# STM32WL31 register map
File version: 1.1
CPU: CM0+ r0p0, little endian, MPU, no FPU, 4 interrupt priority bits
Registers are 32-bit, read-write, reset 0x0 unless marked. A register's access mark holds for its fields unless they carry their own. Offsets are from the block's base; [hi:lo] are bit positions.

## RCC
Base 0x48400000
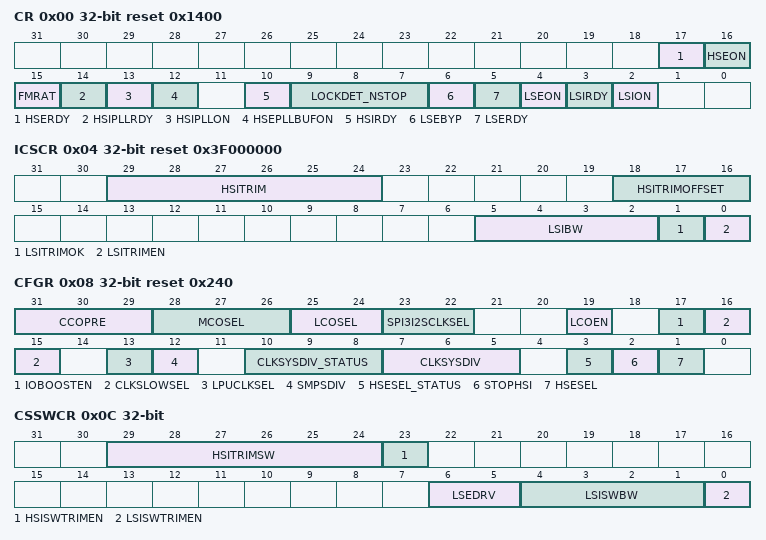
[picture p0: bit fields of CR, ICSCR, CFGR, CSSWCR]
0x00 CR reset 0x1400
  [17] HSERDY ro — External High Speed Clock ready flag. Set by hardware to indicate that HSE oscillator is stable. 0: HSE oscillator not ready 1: HSE oscillator ready
  [16] HSEON — External High Speed Clock enable. Set and reset by software. in low power mode, HSE is turned off. HSE is turned ON only when RFSUBG LDO is Ready 0: HSE oscillator OFF 1: HSE oscillator ON
  [15] FMRAT — Force MRSUBG accurate clock ready status (for debug purpose) 0: no effect 1: active_transmission is force to '1' whatever the HSIPLLRDY/HSE status
  [14] HSIPLLRDY ro — Internal High Speed Clock PLL ready flag. 0: PLL is unlocked 1: PLL is locked
  [13] HSIPLLON — Internal High Speed Clock PLL enable 0: PLL is OFF 1: PLL is ON
  [12] HSEPLLBUFON — External High Speed Clock Buffer for PLL RF enable. Set and reset by software. 0: HSE PLL Buffer OFF 1: HSE PLL Buffer ON (default)
  [10] HSIRDY ro — Internal High Speed clock ready flag. Set by hardware to indicate that internal RC 64MHz oscillator is stable. This bit is activated only if the RC is enabled by HSION (it is not activated if the RC is enabled by an IP request). 0: internal RC 64 MHz oscillator not ready 1: internal RC 64 MHz oscillator ready
  [9:7] LOCKDET_NSTOP — Lock detector Nstop value When start_stop signal is high; a counter is incremented every 16 MHz clock cycle. When the counter reaches (NSTOP+1) x 64 value, the lock_det signal is set high indicating that the PLL is locked. As soon as the start_stop signal is low the counter is reset to 0.
  [6] LSEBYP — External Low Speed Clock bypass. Set and reset by software. Reset source only for this field: PORESETn 0: LSE oscillator bypass OFF 1: LSE oscillator bypass ON Note that enablng this bit, the configuration of PB13 will be bypassed (whatever DFTMUX or AF selection)
  [5] LSERDY ro — External Low Speed Clock ready flag. Set by hardware to indicate that LSE oscillator is stable. 0: LSE oscillator not ready 1: LSE oscillator ready
  [4] LSEON — External Low Speed Clock enable. Set and reset by software. Reset source only for this field: PORESETn 0: LSE oscillator OFF 1: LSE oscillator ON Note that enablng this bit, the configuration of PB12 and PB13 will be bypassed (whatever DFTMUX or AF selection)
  [3] LSIRDY ro — Internal Low Speed oscillator Ready Set and reset by hardware to indicate when the Low Speed Internal RC oscillator is stable. Reset source only for this field: PORESETn 0: LSI RC oscillator not ready 1: LSI RC oscillator ready
  [2] LSION — Internal Low Speed oscillator enable Set and reset by software. Reset source only for this field: PORESETn 0: LSI RC oscillator OFF 1: LSI RC oscillator ON
0x04 ICSCR reset 0x3F000000
  [29:24] HSITRIM ro — High Speed Internal clock trimming. This value is loaded soon after the completion of the Option Byte Loading procedure. When max value 0x3f is set, HSI is less than 64MHz
  [18:16] HSITRIMOFFSET — ICSCR[18:16] = HSITRIMOFFSET[2:0]: High Speed oscillator signed trimming offset 000: 0 (+ 0 MHz / default) 001: 1 (-0.5 MHz) 010: 2 (-1MHz) 011: 3 (-1.5 MHz) 100: -1 (+2 MHz) 101: -2 (+1.5MHz) 110: -3 (+1 MHz) 111: -4 (+0.5 MHz)
  [5:2] LSIBW ro — Trimming in test mode The value stored is the correspondent Engi Byte and represents the actual value driving the input of the hardware macro. This value is loaded soon after the completion of the Option Byte Loading procedure. This field is directly writeable only in Test Mode.
  [1] LSITRIMOK ro — LSITRIMOK: Low Speed oscillator trimming OK Set and reset by hardware to indicate when the Low Speed Internal RC oscillator has reached an optimal trimming of its bias current; this bit is only valid when LSITRIMEN is active. 0: LSI Bias trimming (LSIBW) is not good 1: LSI Bias trimming (LSIBW) value is OK
  [0] LSITRIMEN — Low Speed oscillator trimming enable Set and reset by software. Reset source only for this field: PORESETn 0: LSI oscillator Bias trimming disabled 1: LSI oscillator Bias trimming enabled
0x08 CFGR reset 0x240
  [31:29] CCOPRE — Configurable Clock Output Prescaler. Set and reset by software. Glitches propagation if CCOPRE is modified after CCO output is enabled. 000: CCO clock is divided by 1 001: CCO clock is divided by 2 010: CCO clock is divided by 4 011: CCO clock is divided by 8 100: CCO clock is divided by 16 101: CCO clock is divided by 32 Others: not used
  [28:26] MCOSEL — Main Configurable Clock Output Selection. Set and reset by software. Glitches propagation possible. 000: MCO output disabled, no clock on MCO 001: system clock selected 010: na 011: internal RC 64 MHz (HSI) oscillator clock selected 100: external oscillator (HSE) clock selected 101: internal RC 64 MHz (HSI) oscillator divided by 2048 and used as slow clock selected 110: SMPS clock selected 111: AUX ADC ANA clock selected
  [25:24] LCOSEL — Low speed Configurable Clock Output Selection. Set and reset by software. Glitches propagation possible. Reset source only for this field: PORESETn 00: LCO output disabled, no clock on LCO 01: not used 10: internal 32 KHz (LSI) oscillator clock selected 11: external 32 KHz (LSE) oscillator clock selected
  [23:22] SPI3I2SCLKSEL — SPI3I2SCLKSEL: Selection of I2S clock for SPI3 IP. 00: 32 MHz peripheral clock (default) 01: 16 MHz peripheral clock 10: CLK_SYS 11: CLK_SYS Note: the I2S clock frequency must be higher or equal to the system clock (configured through RCC_CFGR.CLKSYSDIV[2:0] bit field).
  [19] LCOEN — LCOEN: LCO enable on PA10 also in deepstop. 0: LCO output on PA10 is disabled 1: LCO output on PA10 is enabled.
  [17] IOBOOSTEN — IOBOOSTEN: IO BOOSTER enable 0: IO BOOSTER block is disabled 1: IO BOOSTER block is enabled.
  [16:15] CLKSLOWSEL — slow clock source selection Set by software to select the clock source. This is no glitch free mechanism Reset source only for this field: PORESETn 00: '0' (default) 01: LSE oscillator clock used as slow clock 10: LSI oscillator clock used as slow clock 11:HSI_64M divided by 2048 used as slow clock
  [13] LPUCLKSEL — LPUCLKSEL: Selection of LPUART clock 0: 16 MHz peripheral clock (default) 1: LSE clock (Mandatory in LPUART deepstop mode)
  [12] SMPSDIV — SMPS clock prescaling factor to generate 4MHz or 8MHz 0: SMPS clock 8MHz (default ) 1: SMPS clock 4MHz
  [10:8] CLKSYSDIV_STATUS ro — system clock frequency selection status 000: div1 (HSI 64M / HSE 48M) 001: div2 (HSI 32M / HSE 24M) 010: div4/div3 (HSI/HSE) (16M) 011: div8/div6 (HSI/HSE) (8M) 100: div16/div12 (HSI/HSE) (4M) 101: div32/div24 (HSI/HSE) (2M) 110: div64/div48 (HSI/HSE) (1M) Note: behavior depends on depending on CFGR.HSESEL and APB2ENR.MRSUBGEN register
  [7:5] CLKSYSDIV — system clock frequency selection request 000: div1 (HSI 64M / HSE 48M) 001: div2 (HSI 32M / HSE 24M) 010: div4/div3 (HSI/HSE) (16M) 011: div8/div6 (HSI/HSE) (8M) * 100: div16/div12 (HSI/HSE) (4M) * 101: div32/div24 (HSI/HSE) (2M) * 110: div64/div48 (HSI/HSE) (1M) * Note: behavior depends on depending on CFGR.HSESEL and (*) APB2ENR.MRSUBGEN or LPAWUREN register
  [3] HSESEL_STATUS ro — Clock source selection Status 0: HSI clock source is selected 1: HSE clock source is selected Mirror the actual system clock source, depending on clock switching mechanism and limitations
  [2] STOPHSI — Stop HSI clock source request 0: HSI is enabled (default) 1: disable HSI is requested
  [1] HSESEL — Clock source selection request: 0: HSI clock source is requested (default) 1: HSE clock source is requested
0x0C CSSWCR
  [29:24] HSITRIMSW — High Speed Internal clock trimming value to set by SW.
  [23] HSISWTRIMEN — High Speed oscillator trimming by SW enable Set and reset by software. 0: HSI oscillator Bias trimming by SW disabled 1: HSI oscillator Bias trimming by SW enabled
  [6:5] LSEDRV — Maximum Crystal gm for Low Speed External XO (to connect to XTDRV of 32kHz LSE XO => into IO V33?) to amplify drinving capacity modulation Set by software. Reset source only for this field: PORESETn 00: 0.0, low drive capability 01: 0.1, medium low drive capability 10: 1.0, medium high drive capability 11: 1.1, highdrive capability
  [4:1] LSISWBW — Low Speed Internal clock trimming value to set by SW Reset source only for this field: PORESETn
  [0] LSISWTRIMEN — Low Speed oscillator trimming by SW enable Set and reset by software. Reset source only for this field: PORESETn 0: LSI oscillator Bias trimming by SW disabled 1: LSI oscillator Bias trimming by SW enabled
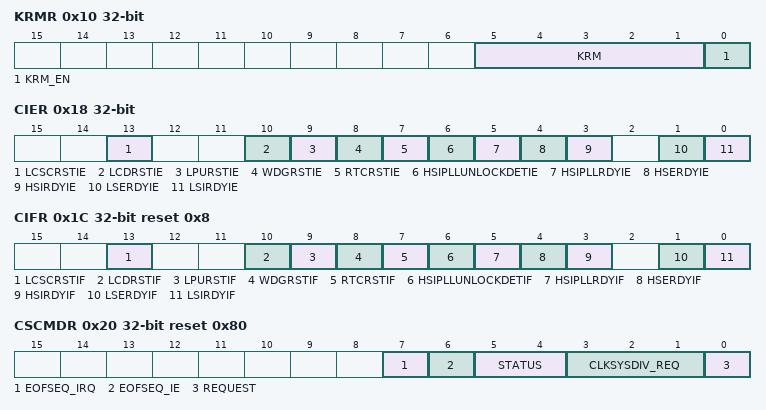
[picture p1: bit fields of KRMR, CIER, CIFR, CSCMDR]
0x10 KRMR
  [5:1] KRM — KRM[4:0] :SMPS clock dividing Ratio (CLK_SPMS_KRM frequency= CLK_ROOT frequency (depending on RCC_CFGR.HSESEL) divided by KRM when KRMEN=1) Reset source only for this field: PORESETn - 0x00 to 0x08: SMPS clock frequency equals CLK_ROOT/8 (8.00 MHz / 6.00 MHz) - 0x09: SMPS clock frequency equals CLK_ROOT/9 (7.11 MHz / 5.33 MHz) - 0x0A: SMPS clock frequency equals CLK_ROOT/10 (6.40 MHz / 4.80 MHz) - 0x0B: SMPS clock frequency equals CLK_ROOT/11 (5.82 MHz / 4.36 MHz) - 0x0C: SMPS clock frequency equals CLK_ROOT/12 (5.33 MHz / 4.00 MHz) - 0x0D: SMPS clock frequency equals CLK_ROOT/13 (4.92 MHz / 3.69 MHz) - 0x0E: SMPS clock frequency equals CLK_ROOT/14 (4.57 MHz / 3.43 MHz) - 0x0F: SMPS clock frequency equals CLK_ROOT/15 (4.27 MHz / 3.20 MHz) - 0x10: SMPS clock frequency equals CLK_ROOT/16 (4.00 MHz / 3.00 MHz) - 0x1x: Reserved Note: SMPS clock frequency must be selected in a range [4-8] MHz (depending on RCC_KRMR.KRM and RCC_CFGR.HSESEL).
  [0] KRM_EN — KRM_EN: Variable rate multiplier Enable Reset source only for this field: PORESETn 0: KRM is disabled (default) 1: KRM is enabled.
0x18 CIER
  [13] LCSCRSTIE — LCSCRSTIE: LCSC reset release interrupt enable. 0: LCSC reset release interrupt is disabled. 1: LCSC reset release interrupt is enabled.
  [10] LCDRSTIE — LCDRSTIE: LCD reset end Interrupt Enable. Set and reset by software to enable/disable interrupt caused by the LCD reset end. 0: interrupt disabled 1: interrupt enabled
  [9] LPURSTIE — LPURSTIE: LPUART reset end Interrupt Enable. Set and reset by software to enable/disable interrupt caused by the LPUART reset end. 0: interrupt disabled 1: interrupt enabled
  [8] WDGRSTIE — WDGRSTIE: Watchdog reset end Interrupt Enable. Set and reset by software to enable/disable interrupt caused by the watchdog reset end. 0: interrupt disabled 1: interrupt enabled
  [7] RTCRSTIE — RTCRSTIE: RTC reset end Interrupt Enable. Set and reset by software to enable/disable interrupt caused by the RTC reset end. 0: HSI PLL unlock detection interrupt disabled 1: HSI PLL unlock detection interrupt enabled
  [6] HSIPLLUNLOCKDETIE — HSIPLLUNLOCKDETIE: HSI PLL unlock detection Interrupt Enable. Set and reset by software to enable/disable interrupt caused by the HSI 64MHz PLL unlock. 0: HSI PLL unlock detection interrupt disabled 1: HSI PLL unlock detection interrupt enabled
  [5] HSIPLLRDYIE — HSI PLL Ready Interrupt Enable. Set and reset by software to enable/disable interrupt caused by the HSI 64MHz PLL locked on HSE. 0: HSI PLL ready interrupt disabled 1: HSI PLL ready interrupt enabled
  [4] HSERDYIE — HSE Ready Interrupt Enable Set and reset by software to enable/disable interrupt caused by the external HSE oscillator stabilization. 0: HSE ready interrupt disabled 1: HSE ready interrupt enabled
  [3] HSIRDYIE — HSI Ready Interrupt Enable. Set and reset by software to enable/disable interrupt caused by the internal RC 64MHz oscillator stabilization. 0: HSI ready interrupt disabled 1: HSI ready interrupt enabled
  [1] LSERDYIE — LSE Ready Interrupt Enable. Set and reset by software to enable/disable interrupt caused by the external 32 kHz oscillator stabilization. 0: LSE ready interrupt disabled 1: LSE ready interrupt enabled
  [0] LSIRDYIE — LSI Ready Interrupt Enable. Set and reset by software to enable/disable interrupt caused by internal RC 32 kHz oscillator stabilization. 0: LSI ready interrupt disabled 1: LSI ready interrupt enabled
0x1C CIFR reset 0x8
  [13] LCSCRSTIF — LCSC reset end Interrupt Flag. Raised when reset is released on 32kHz clock
  [10] LCDRSTIF — LCD reset end Interrupt Flag. Raised when reset is released on 32kHz clock
  [9] LPURSTIF — LPUART reset end Interrupt Flag. Raised when reset is released on 32kHz clock
  [8] WDGRSTIF — WDG reset end Interrupt Flag. Raised when reset is released on 32kHz clock
  [7] RTCRSTIF — RTC reset end Interrupt Flag. Raised when reset is released on 32kHz clock
  [6] HSIPLLUNLOCKDETIF — HSIPLLUNLOCKDETIF: HSI PLL unlock detection Interrupt Flag.
  [5] HSIPLLRDYIF — HSI PLL Ready Interrupt Flag. Set by hardware when HSI PLL 64MHz becomes stable. 0: No clock ready interrupt caused by the HSI PLL64 MHz oscillator 1: Clock ready interrupt caused by the HSI PLL64 MHz oscillator
  [4] HSERDYIF — HSE Ready Interrupt Flag. Set by hardware when HSE becomes stable. 0: No clock ready interrupt caused by the HSE oscillator 1: Clock ready interrupt caused by the HSE oscillator
  [3] HSIRDYIF — HSI Ready Interrupt Flag. Set by hardware when HSI becomes stable. 0: No clock ready interrupt caused by the HSI oscillator 1: Clock ready interrupt caused by the HSI oscillator
  [1] LSERDYIF — LSE Ready Interrupt Flag. Set by hardware when LSE clock becomes stable. 0: No clock ready interrupt caused by the LSE oscillator 1: Clock ready interrupt caused by the LSE oscillator
  [0] LSIRDYIF — LSI Ready Interrupt flag Set by hardware when LSI clock becomes stable. 0: No clock ready interrupt caused by the internal RC 32 KHz oscillator 1: Clock ready interrupt caused by the internal RC 32 kHz oscillator
0x20 CSCMDR reset 0x80
  [7] EOFSEQ_IRQ — End of Sequence flag Set by hardware when clock system swtich is ended 0: No end of sequence event occured 1: End of sequece event occured
  [6] EOFSEQ_IE — End of sequence Interrupt Enable. Set and reset by software to enable/disable interrupt caused by the clock system switch. 0: End of sequence interrupt disabled 1: End of sequence interrupt enabled
  [5:4] STATUS ro — Status of clock switch sequence 00: IDLE no switch requested 01: ONGOING clock frequency switch is ongoing 10: DONE clock frequency switch done 11: Reserved
  [3:1] CLKSYSDIV_REQ — system clock frequency selection request 000: div1 (HSI 64M / HSE) (48M) 001: div2 (HSI 32M / HSE (24M*) 010: div4/div3 (HSI/HSE) (16M) 011: div8/div6 (HSI/HSE) (8M) * 100: div16/div12 (HSI/HSE) (4M) * 101: div32/div24 (HSI/HSE) (2M) * 110: div64/div48 (HSI/HSE) (1M) * Note: behavior depends on depending on CFGR.HSESEL and (*) APB2ENR.MRSUBGEN or LPAWUREN
  [0] REQUEST — Request for system clock switching Cleared by hardware when system clock frequency switch is done 0: To cancel an ongiong request - still possible until IRQ assertion 1: To update the system clock frequency
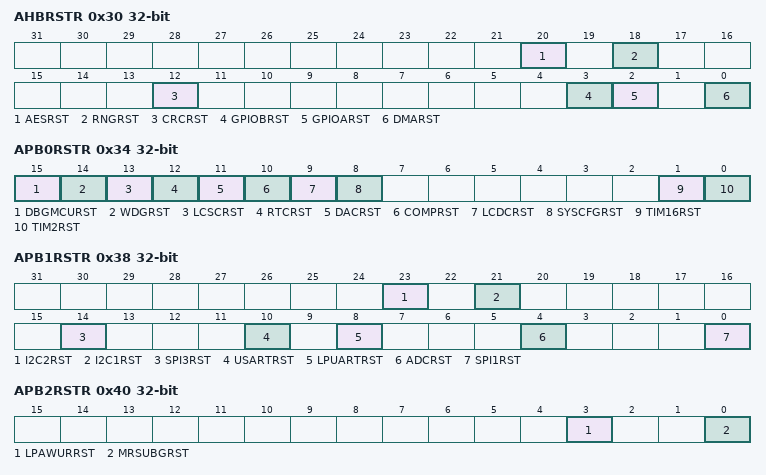
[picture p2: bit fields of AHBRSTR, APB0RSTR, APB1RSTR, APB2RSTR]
0x30 AHBRSTR
  [20] AESRST — AES reset Set and reset by software. 0: IP is not under reset. 1: IP is under reset.
  [18] RNGRST — RNG reset Set and reset by software. 0: IP is not under reset. 1: IP is under reset.
  [12] CRCRST — CRC reset Set and reset by software. 0: IP is not under reset. 1: IP is under reset.
  [3] GPIOBRST — GPIOB reset Set and reset by software. 0: IP is not under reset. 1: IP is under reset.
  [2] GPIOARST — GPIOA reset Set and reset by software. 0: IP is not under reset. 1: IP is under reset.
  [0] DMARST — DMA and DMAMUX reset Set and reset by software. 0: IP is not under reset. 1: IP is under reset.
0x34 APB0RSTR
  [15] DBGMCURST — DBGMCURST: DBGMCU reset. 0: DBGMCU IP is not under reset. 1: DBGMCU IP is under reset.
  [14] WDGRST — WDGRST: Watchdog reset. 0: Watchdog IP is not under reset. 1: Watchdog IP is under reset.
  [13] LCSCRST — LCSCRST: LCSC reset. 0: LCSC IP is not under reset. 1: LCSC IP is under reset.
  [12] RTCRST — RTCRST: RTC reset. 0: RTC IP is not under reset. 1: RTC IP is under reset.
  [11] DACRST — DACRST: DAC reset. 0: DAC IP is not under reset. 1: DAC IP is under reset.
  [10] COMPRST — COMPRST: COMP reset. 0: COMP IP is not under reset. 1: COMP IP is under reset.
  [9] LCDCRST — LCDCRST: LCD controller reset. 0: LCD controller IP is not under reset. 1: LCD controller IP is under reset.
  [8] SYSCFGRST — SYSCFGRST: system controller reset. 0: system controller IP is not under reset. 1: system controller IP is under reset.
  [1] TIM16RST — TIM16RST: TIM16 reset. 0: TIM16 IP is not under reset. 1: TIM16 IP is under reset.
  [0] TIM2RST — TIM2RST: TIM2 reset. 0: TIM2 IP is not under reset. 1: TIM2 IP is under reset.
0x38 APB1RSTR
  [23] I2C2RST — I2C2 reset Set and reset by software. 0: IP is not under reset. 1: IP is under reset.
  [21] I2C1RST — I2C1 reset Set and reset by software. 0: IP is not under reset. 1: IP is under reset.
  [14] SPI3RST — SPI3 reset Set and reset by software. 0: IP is not under reset. 1: IP is under reset.
  [10] USARTRST — USART reset Set and reset by software. 0: IP is not under reset. 1: IP is under reset.
  [8] LPUARTRST — LPUART reset Set and reset by software. 0: IP is not under reset. 1: IP is under reset.
  [4] ADCRST — ADC reset for Aux-ADC IP Set and reset by software. 0: IP is not under reset. 1: IP is under reset.
  [0] SPI1RST — SPI1 reset Set and reset by software. 0: IP is not under reset. 1: IP is under reset.
0x40 APB2RSTR
  [3] LPAWURRST — Bubble reset Set and reset by software. 0: IP is not under reset. 1: IP is under reset.
  [0] MRSUBGRST — Radio MRSUBG reset. Set and reset by software. 0: IP is not under reset. 1: IP is under reset.
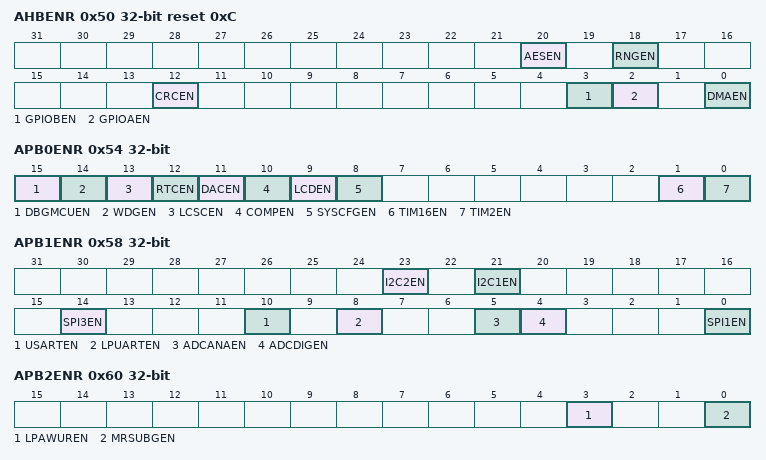
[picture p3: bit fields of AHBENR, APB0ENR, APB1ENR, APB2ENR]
0x50 AHBENR reset 0xC
  [20] AESEN — AESEN: AES clock enable. 0: AES IP is clock gated. 1: AES IP is clocked.
  [18] RNGEN — RNG clock enable Set and enable by software. 0: does not enable 1: enable
  [12] CRCEN — CRC enable Set and enable by software. 0: does not enable 1: enable
  [3] GPIOBEN — GPIOB enable. It must be enabled by default
  [2] GPIOAEN — GPIOA enable. It must be enabled by default
  [0] DMAEN — DMA and DMAMUX enable Set and enable by software. 0: does not enable 1: enable
0x54 APB0ENR
  [15] DBGMCUEN — DBG MCU clock enable. Set and enable by software. 0: clock disable 1: clock enable
  [14] WDGEN — Watchdog clock enable. Set and enable by software. 0: clock disable 1: clock enable
  [13] LCSCEN — LCSC clock enable. Set and enable by software. 0: clock disable 1: clock enable
  [12] RTCEN — RTC clock enable Set and enable by software. Reset source only for this field: PORESETn 0: clock disable 1: clock enable
  [11] DACEN — DAC clock enable Set and enable by software. 0: clock disable 1: clock enable
  [10] COMPEN — COMP clock enable Set and enable by software. 0: clock disable 1: clock enable
  [9] LCDEN — LCD clock enable Set and enable by software. 0: clock disable 1: clock enable
  [8] SYSCFGEN — SYSTEM CONFIG clock enable Set and enable by software. 0: clock disable 1: clock enable
  [1] TIM16EN — TIM16: Advanced Timer clock enable Set and enable by software. 0: clock disable 1: clock enable
  [0] TIM2EN — TIM2: Advanced Timer clock enable Set and enable by software. 0: clock disable 1: clock enable
0x58 APB1ENR
  [23] I2C2EN — I2C2 clock enable Set and enable by software. 0: clock disable 1: clock enable
  [21] I2C1EN — I2C1 clock enable Set and enable by software. 0: clock disable 1: clock enable
  [14] SPI3EN — SPI3 clock enable Set and enable by software. 0: clock disable 1: clock enable
  [10] USARTEN — USART clock enable Set and enable by software. 0: clock disable 1: clock enable
  [8] LPUARTEN — LPUART clock enable Set and enable by software. 0: clock disable 1: clock enable
  [5] ADCANAEN — ADC clock enable for Aux-ADC analog clock Set and enable by software. 0: clock disable 1: clock enable
  [4] ADCDIGEN — AUXADC clock enable for Aux-ADC digital clock Set and enable by software. 0: clock disable 1: clock enable
  [0] SPI1EN — SPI1 clock enable Set and enable by software. 0: clock disable 1: clock enable
0x60 APB2ENR
  [3] LPAWUREN — Bubble clock enable Set and enable by software. 0: clock disable 1: clock enable
  [0] MRSUBGEN — MRSUBG clock enable. Note: when this bit is '1', it must prevent clk_sys different from 16, 32, 64. If the configured clock is lower than 16MHz (1, 2, 4 or 8 MHz) or equal to 24MHz, clk_sys must be 16MHz 0: clock disable 1: clock enable
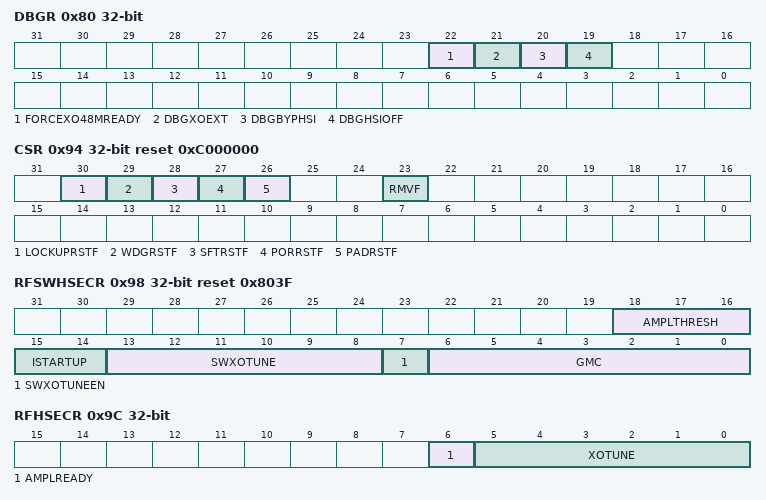
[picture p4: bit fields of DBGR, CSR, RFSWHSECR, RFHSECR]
0x80 DBGR
  [22] FORCEXO48MREADY — FORCEXO48MREADY Force XO48M Ready input signal This bit is for debug and force the XO48M ready input, in order to bypass XO48M comparators. 0: No effect (default) 1: Force XOREADY=1
  [21] DBGXOEXT — used for debug mode with HSE bypassed by FXTAL_IN clock and ZIV12 output used. 0: No effect (default) 1: HSE bypassed by FXTAL_IN clock and ZIV12 output used.
  [20] DBGBYPHSI — used for debug mode with HSI bypassed by HSE 0: No effect (default) 1: HSI bypassed HSE.
  [19] DBGHSIOFF — used for debug or test 0: No effect (default) 1: HSI forced off.
0x94 CSR reset 0xC000000
  [30] LOCKUPRSTF ro — LOCK UP reset flag from CM0 Reset by software by writing the RMVF bit. Set by hardware from unrecoverable exception CPU. It reset V12i domain, FLASH controller and peripherals. 0: No lockup reset occurred 1: lockup reset occurred
  [29] WDGRSTF ro — Watchdog reset flag Reset by software by writing the RMVF bit. Set by hardware when a watchdog reset from V33 domain occurs. 0: No watchdog reset occurred 1: Watchdog reset occurred
  [28] SFTRSTF ro — Software reset flag Reset by software by writing the RMVF bit. Set by hardware when a software reset occurs. 0: No software reset occurred 1: Software reset occurred
  [27] PORRSTF ro — POWER reset flag Reset by software by writing the RMVF bit. Set by hardware when a power reset occurs from LPMURESET block. 0: No POWER reset occurred 1: POWER reset occurred
  [26] PADRSTF ro — SYSTEM reset flag Reset by software by writing the RMVF bit. Set by hardware when a reset from pad occurs. 0: No reset from pad occurred 1: Reset from pad occurred
  [23] RMVF wo — Remove reset flag Set by software to clear the value of the reset flags. It auto clears by HW after clearing reason flags 0: Nothing done 1: Reset the value of the reset flags
0x98 RFSWHSECR reset 0x803F
  [18:16] AMPLTHRESH — RF-HSE Amplitude Control threshold Set by software Default value 0
  [15:14] ISTARTUP — RF-HSE Startup current Set by software Default value 2
  [13:8] SWXOTUNE — RF-HSE capacitor bank tuning value by SW Set by software
  [7] SWXOTUNEEN — RF-HSE capacitor bank tuning by SW enable Set by software
  [6:0] GMC — GMC[6:5]: High speed external XO current control reference 00: 10 uA 01: 20 uA 1x: 40 uA GMC[4:0]: High speed external XO current control multiplying factor IcoreHSE= GMC[4:0] * GMC[6:5] Example: GMC[6:0]=0x1111001 -> IcoreHSE=25*40uA / Default 3F: IcoreHSE= 10uA x 31 = 310uA Note: this value is set only by software.
0x9C RFHSECR ro
  [6] AMPLREADY — RF-HSE Amplitude Control Ready output
  [5:0] XOTUNE — RF-HSE capacitor bank tuning Set by option byte loading soon after Power On Reset.
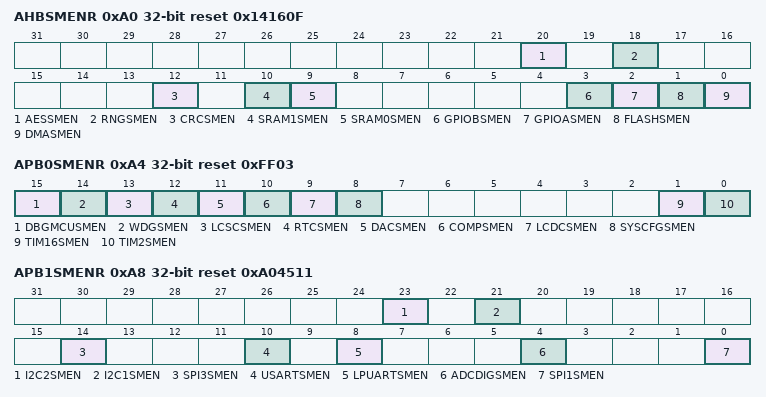
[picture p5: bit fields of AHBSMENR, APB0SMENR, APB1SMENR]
0xA0 AHBSMENR reset 0x14160F
  [20] AESSMEN — AES bus clock enable during Sleep mode bit This bit is set and reset by software. - 0: AES bus clock disabled in Sleep mode - 1: AES bus clock enabled in Sleep mode (if enabled in AESEN)
  [18] RNGSMEN — RNG bus clock enable during Sleep mode bit This bit is set and reset by software. - 0: RNG bus clock disabled in Sleep mode - 1: RNG bus clock enabled in Sleep mode (if enabled in RNGEN)
  [12] CRCSMEN — CRC clock enable during Sleep mode bit This bit is set and reset by software. - 0: CRC clock disabled in Sleep mode - 1: CRC clock enabled in Sleep mode (if enabled in CRCEN)
  [10] SRAM1SMEN — SRAM1 clock enable during Sleep mode bit This bit is set and reset by software. - 0: SRAM1 clock disabled in Sleep mode - 1: SRAM1 clock enabled in Sleep mode
  [9] SRAM0SMEN — SRAM0 clock enable during Sleep mode bit This bit is set and reset by software. - 0: SRAM0 clock disabled in Sleep mode - 1: SRAM0 clock enabled in Sleep mode
  [3] GPIOBSMEN — GPIOB clock enable during Sleep mode bit This bit is set and reset by software. - 0: GPIOB clock disabled in Sleep mode - 1: GPIOB clock enabled in Sleep mode (if enabled in GPIOBEN)
  [2] GPIOASMEN — GPIOA clock enable during Sleep mode bit This bit is set and reset by software. - 0: GPIOA clock disabled in Sleep mode - 1: GPIOA clock enabled in Sleep mode (if enabled by GPIOAEN)
  [1] FLASHSMEN — Flash clocks enable during Flash Sleep PD and CPU Sleep mode bit This bit is set and reset by software. - 0: Flash clocks are disabled in Flash Sleep PD* and CPU Sleep mode - 1: Flash clocks are enabled in Sleep mode Note: Flash Sleep PD is enabled through nvm_control register CONFIG.SLEEP_PD
  [0] DMASMEN — DMA clock enable during Sleep mode bit This bit is set and reset by software. - 0: DMA clock disabled in Sleep mode - 1: DMA clock enabled in Sleep mode (if enabled in DMAEN)
0xA4 APB0SMENR reset 0xFF03
  [15] DBGMCUSMEN — DBGMCU clock enable during Sleep mode bit This bit is set and reset by software. - 0: DBGMCU clock disabled in Sleep mode - 1: DBGMCU clock enabled in Sleep mode (if enabled in DBGMCUEN)
  [14] WDGSMEN — WDG clock enable during Sleep mode bit This bit is set and reset by software. - 0: WDG clock disabled in Sleep mode - 1: WDG clock enabled in Sleep mode (if enabled in WDGEN)
  [13] LCSCSMEN — LCSC bus clock enable during Sleep mode bit This bit is set and reset by software. - 0: LCSC bus clock disabled in Sleep mode - 1: LCSC bus clock enabled in Sleep mode (if enabled in LCSCEN)
  [12] RTCSMEN — RTC bus clock enable during Sleep mode bit This bit is set and reset by software. - 0: RTC bus clock disabled in Sleep mode - 1: RTC bus clock enabled in Sleep mode (if enabled in RTCEN)
  [11] DACSMEN — DAC bus clock enable during Sleep mode bit This bit is set and reset by software. - 0: DAC bus clock disabled in Sleep mode - 1: DAC bus clock enabled in Sleep mode (if enabled in DACEN)
  [10] COMPSMEN — COMP bus clock enable during Sleep mode bit This bit is set and reset by software. - 0: COMP bus clock disabled in Sleep mode - 1: COMP bus clock enabled in Sleep mode (if enabled in COMPEN)
  [9] LCDCSMEN — LCDC bus clock enable during Sleep mode bit This bit is set and reset by software. - 0: LCDC bus clock disabled in Sleep mode - 1: LCDC bus clock enabled in Sleep mode (if enabled in LCDCEN)
  [8] SYSCFGSMEN — SYSCFG bus clock enable during Sleep mode bit This bit is set and reset by software. - 0: SYSCFG bus clock disabled in Sleep mode - 1: SYSCFG bus clock enabled in Sleep mode (if enabled in SYSCFGEN)
  [1] TIM16SMEN — TIM16 bus clock enable during Sleep mode bit This bit is set and reset by software. - 0: TIM16 bus clock disabled in Sleep mode - 1: TIM16 bus clock enabled in Sleep mode (if enabled in TIM16EN)
  [0] TIM2SMEN — TIM2 bus clock enable during Sleep mode bit This bit is set and reset by software. - 0: TIM2 bus clock disabled in Sleep mode - 1: TIM2 bus clock enabled in Sleep mode (if enabled in TIM2EN)
0xA8 APB1SMENR reset 0xA04511
  [23] I2C2SMEN — I2C2 clock enable during Sleep mode bit This bit is set and reset by software. - 0: I2C2 clock disabled in Sleep mode - 1: I2C2 clock enabled in Sleep mode (if enabled in I2C2EN)
  [21] I2C1SMEN — I2C1 clock enable during Sleep mode bit This bit is set and reset by software. - 0: I2C1 clock disabled in Sleep mode - 1: I2C1 clock enabled in Sleep mode (if enabled in I2C1EN)
  [14] SPI3SMEN — SPI3 bus clock enable during Sleep mode bit This bit is set and reset by software. - 0: SPI3 bus clock disabled in Sleep mode - 1: SPI3 bus clock enabled in Sleep mode (if enabled in SPI3EN)
  [10] USARTSMEN — USART bus clock enable during Sleep mode bit This bit is set and reset by software. - 0: USART bus clock disabled in Sleep mode - 1: USART bus clock enabled in Sleep mode (if enabled in USARTEN)
  [8] LPUARTSMEN — LPUART bus clock enable during Sleep mode bit This bit is set and reset by software. - 0: LPUART bus clock disabled in Sleep mode - 1: LPUART bus clock enabled in Sleep mode (if enabled in LPUARTEN)
  [4] ADCDIGSMEN — ADCDIG bus clock enable during Sleep mode bit This bit is set and reset by software. - 0: ADCDIG bus clock disabled in Sleep mode - 1: ADCDIG bus clock enabled in Sleep mode (if enabled by ADCDIGEN)
  [0] SPI1SMEN — SPI1 bus clock enable during Sleep mode bit This bit is set and reset by software. - 0: SPI1 bus clock disabled in Sleep mode - 1: SPI1 bus clock enabled in Sleep mode (if enabled in SPI1EN)
